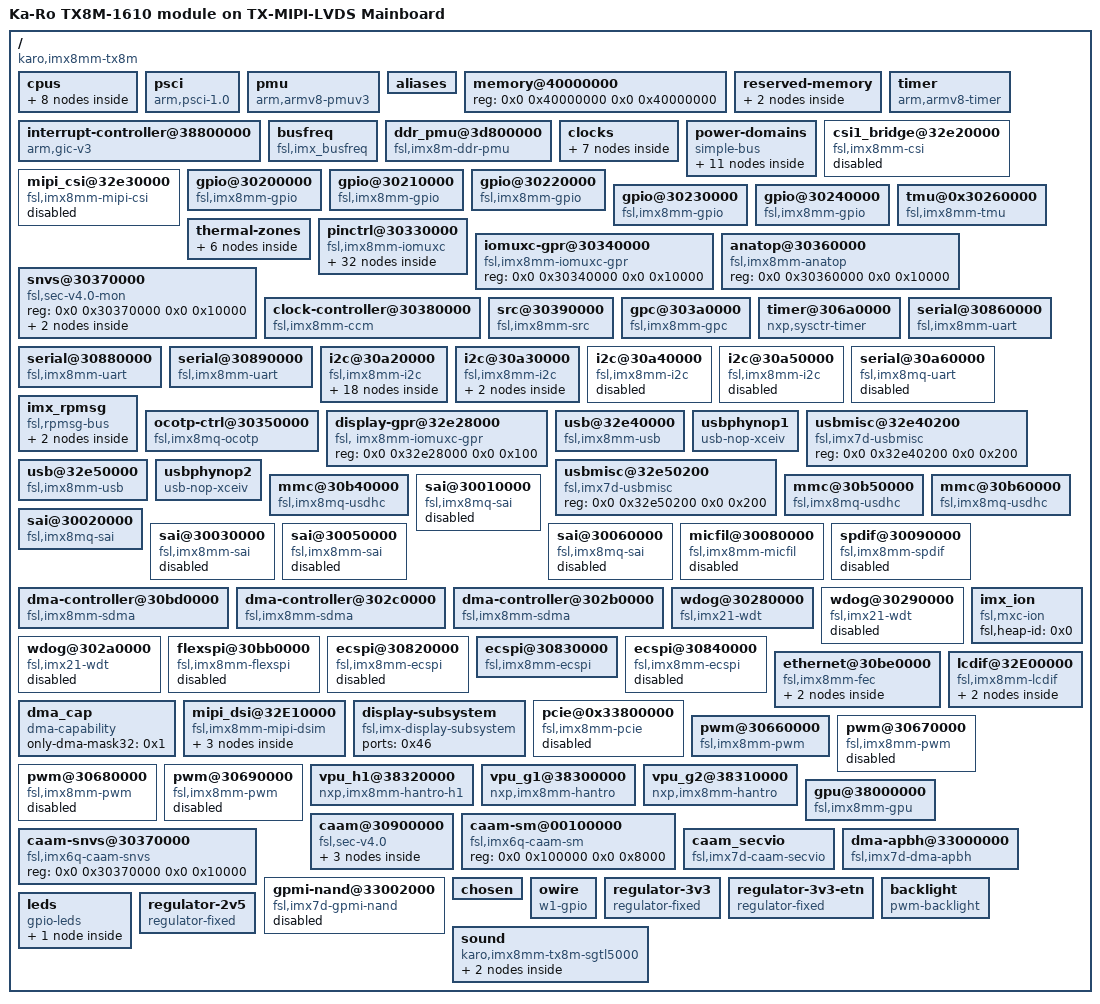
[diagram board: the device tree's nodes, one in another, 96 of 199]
/dts-v1/;

/ {
	compatible = "karo,imx8mm-tx8m", "fsl,imx8mm";
	interrupt-parent = <0x1>;
	#address-cells = <0x2>;
	#size-cells = <0x2>;
	model = "Ka-Ro TX8M-1610 module on TX-MIPI-LVDS Mainboard";

	cpus {
		#address-cells = <0x2>;
		#size-cells = <0x0>;

		idle-states {
			entry-method = "psci";

			cpu-sleep {
				compatible = "arm,idle-state";
				arm,psci-suspend-param = <0x10033>;
				entry-latency-us = <0x61a8>;
				exit-latency-us = <0x2710>;
				min-residency-us = <0x7530>;
				local-timer-stop;
				wakeup-latency-us = <0x3a98>;
			};

			cluster-sleep {
				compatible = "arm,idle-state";
				arm,psci-suspend-param = <0x1000000>;
				entry-latency-us = <0x3e8>;
				exit-latency-us = <0x2bc>;
				min-residency-us = <0xa8c>;
				wakeup-latency-us = <0x5dc>;
			};
		};

		cpu@0 {
			device_type = "cpu";
			compatible = "arm,cortex-a53";
			reg = <0x0 0x0>;
			enable-method = "psci";
			next-level-cache = <0x2>;
			operating-points = <0x1b7740 0xf4240 0x186a00 0xdbba0 0x124f80 0xc3500>;
			clocks = <0x3 0x4c 0x3 0x42 0x3 0x18 0x3 0x2c 0x3 0x38>;
			clock-names = "a53", "arm_a53_src", "arm_pll", "arm_pll_out", "sys1_pll_800m";
			clock-latency = <0xee6c>;
			#cooling-cells = <0x2>;
			arm-supply = <0x4>;
			linux,phandle = <0x5>;
			phandle = <0x5>;
		};

		cpu@1 {
			device_type = "cpu";
			compatible = "arm,cortex-a53";
			reg = <0x0 0x1>;
			enable-method = "psci";
			next-level-cache = <0x2>;
			linux,phandle = <0x6>;
			phandle = <0x6>;
		};

		cpu@2 {
			device_type = "cpu";
			compatible = "arm,cortex-a53";
			reg = <0x0 0x2>;
			enable-method = "psci";
			next-level-cache = <0x2>;
			linux,phandle = <0x7>;
			phandle = <0x7>;
		};

		cpu@3 {
			device_type = "cpu";
			compatible = "arm,cortex-a53";
			reg = <0x0 0x3>;
			enable-method = "psci";
			next-level-cache = <0x2>;
			linux,phandle = <0x8>;
			phandle = <0x8>;
		};

		l2-cache0 {
			compatible = "cache";
			linux,phandle = <0x2>;
			phandle = <0x2>;
		};
	};

	psci {
		compatible = "arm,psci-1.0";
		method = "smc";
		cpu_suspend = <0xc4000001>;
		cpu_off = <0xc4000002>;
		cpu_on = <0xc4000003>;
	};

	pmu {
		compatible = "arm,armv8-pmuv3";
		interrupts = <0x1 0x7 0x3f04>;
		interrupt-affinity = <0x5 0x6 0x7 0x8>;
		interrupt-parent = <0x9>;
	};

	aliases {
		ethernet0 = "/ethernet@30be0000";
		i2c0 = "/i2c@30a20000";
		i2c1 = "/i2c@30a30000";
		i2c2 = "/i2c@30a40000";
		i2c3 = "/i2c@30a50000";
		serial0 = "/serial@30860000";
		serial1 = "/serial@30890000";
		serial2 = "/serial@30880000";
		serial3 = "/serial@30a60000";
		spi0 = "/ecspi@30820000";
		spi1 = "/ecspi@30830000";
		spi2 = "/ecspi@30840000";
		mmc0 = "/mmc@30b40000";
		mmc1 = "/mmc@30b50000";
		mmc2 = "/mmc@30b60000";
		gpio0 = "/gpio@30200000";
		gpio1 = "/gpio@30210000";
		gpio2 = "/gpio@30220000";
		gpio3 = "/gpio@30230000";
		gpio4 = "/gpio@30240000";
		usb-host = "/usb@32e50000";
		usbotg = "/usb@32e40000";
	};

	memory@40000000 {
		device_type = "memory";
		reg = <0x0 0x40000000 0x0 0x40000000>;
	};

	reserved-memory {
		#address-cells = <0x2>;
		#size-cells = <0x2>;
		ranges;

		linux,cma {
			compatible = "shared-dma-pool";
			reusable;
			size = <0x0 0x28000000>;
			alloc-ranges = <0x0 0x40000000 0x0 0x60000000>;
			linux,cma-default;
		};

		rpmsg@0xb8000000 {
			no-map;
			reg = <0x0 0xb8000000 0x0 0x400000>;
			linux,phandle = <0x47>;
			phandle = <0x47>;
		};
	};

	interrupt-controller@38800000 {
		compatible = "arm,gic-v3";
		reg = <0x0 0x38800000 0x0 0x10000 0x0 0x38880000 0x0 0xc0000>;
		#interrupt-cells = <0x3>;
		interrupt-controller;
		interrupts = <0x1 0x9 0x4>;
		interrupt-parent = <0x9>;
		linux,phandle = <0x9>;
		phandle = <0x9>;
	};

	timer {
		compatible = "arm,armv8-timer";
		interrupts = <0x1 0xd 0x3f08 0x1 0xe 0x3f08 0x1 0xb 0x3f08 0x1 0xa 0x3f08>;
		clock-frequency = <0x7a1200>;
		arm,no-tick-in-suspend;
		interrupt-parent = <0x9>;
	};

	busfreq {
		compatible = "fsl,imx_busfreq";
		clocks = <0x3 0x29 0x3 0x90 0x3 0x91 0x3 0x10b 0x3 0x1c5 0x3 0x1c6 0x3 0x30 0x3 0x32 0x3 0x3f 0x3 0x7f 0x3 0x8a 0x3 0x51 0x3 0x2 0x3 0x38>;
		clock-names = "dram_pll", "dram_alt_src", "dram_apb_src", "dram_apb_pre_div", "dram_core", "dram_alt_root", "sys_pll1_40m", "sys_pll1_100m", "sys_pll2_333m", "noc_div", "ahb_div", "main_axi_src", "osc_24m", "sys_pll1_800m";
		interrupts = <0x0 0x4a 0x4 0x0 0x4b 0x4 0x0 0x4c 0x4 0x0 0x4d 0x4>;
		interrupt-name = "irq_busfreq_0", "irq_busfreq_1", "irq_busfreq_2", "irq_busfreq_3";
	};

	ddr_pmu@3d800000 {
		compatible = "fsl,imx8m-ddr-pmu", "fsl,imx8-ddr-pmu";
		reg = <0x0 0x3d800000 0x0 0x400000>;
		interrupts = <0x0 0x62 0x4>;
	};

	clocks {
		#address-cells = <0x1>;
		#size-cells = <0x0>;

		clock@0 {
			compatible = "fixed-clock";
			reg = <0x0>;
			#clock-cells = <0x0>;
			clock-frequency = <0x8000>;
			clock-output-names = "osc_32k";
			linux,phandle = <0x11>;
			phandle = <0x11>;
		};

		clock@1 {
			compatible = "fixed-clock";
			reg = <0x1>;
			#clock-cells = <0x0>;
			clock-frequency = <0x16e3600>;
			clock-output-names = "osc_24m";
			linux,phandle = <0x12>;
			phandle = <0x12>;
		};

		clock@2 {
			compatible = "fixed-clock";
			reg = <0x3>;
			#clock-cells = <0x0>;
			clock-frequency = <0x7ed6b40>;
			clock-output-names = "clk_ext1";
			linux,phandle = <0x13>;
			phandle = <0x13>;
		};

		clock@3 {
			compatible = "fixed-clock";
			reg = <0x4>;
			#clock-cells = <0x0>;
			clock-frequency = <0x7ed6b40>;
			clock-output-names = "clk_ext2";
			linux,phandle = <0x14>;
			phandle = <0x14>;
		};

		clock@4 {
			compatible = "fixed-clock";
			reg = <0x5>;
			#clock-cells = <0x0>;
			clock-frequency = <0x7ed6b40>;
			clock-output-names = "clk_ext3";
			linux,phandle = <0x15>;
			phandle = <0x15>;
		};

		clock@5 {
			compatible = "fixed-clock";
			reg = <0x6>;
			#clock-cells = <0x0>;
			clock-frequency = <0x7ed6b40>;
			clock-output-names = "clk_ext4";
			linux,phandle = <0x16>;
			phandle = <0x16>;
		};

		clock@6 {
			compatible = "fixed-clock";
			reg = <0x6>;
			#clock-cells = <0x0>;
			clock-frequency = <0x18cba80>;
			linux,phandle = <0x25>;
			phandle = <0x25>;
		};
	};

	power-domains {
		compatible = "simple-bus";
		#address-cells = <0x1>;
		#size-cells = <0x0>;

		power-domain@0 {
			compatible = "fsl,imx8mm-pm-domain";
			#address-cells = <0x1>;
			#size-cells = <0x0>;
			domain-id = <0x0>;
			#power-domain-cells = <0x0>;
			domain-name = "HSIO_PD";
			clocks = <0x3 0x1a5>;

			power-domain@1 {
				domain-id = <0x1>;
				#power-domain-cells = <0x0>;
				domain-name = "PCIE0_PD";
				clocks = <0x3 0x18e>;
				linux,phandle = <0x48>;
				phandle = <0x48>;
			};

			power-domain@2 {
				domain-id = <0x2>;
				#power-domain-cells = <0x0>;
				domain-name = "USB_OTG1_PD";
				linux,phandle = <0x29>;
				phandle = <0x29>;
			};

			power-domain@3 {
				domain-id = <0x3>;
				#power-domain-cells = <0x0>;
				domain-name = "USB_OTG2_PD";
				linux,phandle = <0x2c>;
				phandle = <0x2c>;
			};
		};

		power-domain@4 {
			compatible = "fsl,imx8mm-pm-domain";
			domain-id = <0x4>;
			#power-domain-cells = <0x0>;
			domain-name = "GPUMIX_PD";
			clocks = <0x3 0x1ad 0x3 0x1be 0x3 0x1a6 0x3 0x7e>;
			linux,phandle = <0x4d>;
			phandle = <0x4d>;
		};

		power-domain@5 {
			compatible = "fsl,imx8mm-pm-domain";
			#address-cells = <0x1>;
			#size-cells = <0x0>;
			domain-id = <0x5>;
			#power-domain-cells = <0x0>;
			domain-name = "VPUMIX_PD";
			clocks = <0x3 0x1b7>;

			power-domain@6 {
				domain-id = <0x6>;
				#power-domain-cells = <0x0>;
				domain-name = "VPU_G1_PD";
				clocks = <0x3 0x1ac>;
				linux,phandle = <0x4b>;
				phandle = <0x4b>;
			};

			power-domain@7 {
				domain-id = <0x7>;
				#power-domain-cells = <0x0>;
				domain-name = "VPU_G2_PD";
				clocks = <0x3 0x1af>;
				linux,phandle = <0x4c>;
				phandle = <0x4c>;
			};

			power-domain@8 {
				domain-id = <0x8>;
				#power-domain-cells = <0x0>;
				domain-name = "VPU_H1_PD";
				clocks = <0x3 0x1ae>;
				linux,phandle = <0x4a>;
				phandle = <0x4a>;
			};
		};

		power-domain@9 {
			compatible = "fsl,imx8mm-pm-domain";
			#address-cells = <0x1>;
			#size-cells = <0x0>;
			domain-id = <0x9>;
			#power-domain-cells = <0x0>;
			domain-name = "DISPMIX_PD";
			clocks = <0x3 0x1b1>;
			linux,phandle = <0xa>;
			phandle = <0xa>;

			power-domain@10 {
				domain-id = <0xa>;
				#power-domain-cells = <0x0>;
				domain-name = "MIPI_PD";
				linux,phandle = <0xc>;
				phandle = <0xc>;
			};
		};
	};

	csi1_bridge@32e20000 {
		compatible = "fsl,imx8mm-csi", "fsl,imx8mq-csi", "fsl,imx6s-csi";
		reg = <0x0 0x32e20000 0x0 0x10000>;
		interrupts = <0x0 0x10 0x4>;
		clocks = <0x3 0x1b2 0x3 0x1c0 0x3 0x1b3>;
		clock-names = "disp-axi", "csi_mclk", "disp_dcic";
		power-domains = <0xa>;
		status = "disabled";
	};

	mipi_csi@32e30000 {
		compatible = "fsl,imx8mm-mipi-csi";
		reg = <0x0 0x32e30000 0x0 0x1000>;
		interrupts = <0x0 0x11 0x4>;
		clock-frequency = <0x13d92d40>;
		clocks = <0x3 0x178 0x3 0x179 0x3 0x1b2 0x3 0x1b3>;
		clock-names = "mipi_clk", "phy_clk", "disp_axi", "disp_apb";
		bus-width = <0x4>;
		csi-gpr = <0xb>;
		power-domains = <0xc>;
		status = "disabled";
	};

	gpio@30200000 {
		compatible = "fsl,imx8mm-gpio", "fsl,imx35-gpio";
		reg = <0x0 0x30200000 0x0 0x10000>;
		interrupts = <0x0 0x40 0x4 0x0 0x41 0x4>;
		gpio-controller;
		#gpio-cells = <0x2>;
		interrupt-controller;
		#interrupt-cells = <0x2>;
		linux,phandle = <0x21>;
		phandle = <0x21>;
	};

	gpio@30210000 {
		compatible = "fsl,imx8mm-gpio", "fsl,imx35-gpio";
		reg = <0x0 0x30210000 0x0 0x10000>;
		interrupts = <0x0 0x42 0x4 0x0 0x43 0x4>;
		gpio-controller;
		#gpio-cells = <0x2>;
		interrupt-controller;
		#interrupt-cells = <0x2>;
		linux,phandle = <0x32>;
		phandle = <0x32>;
	};

	gpio@30220000 {
		compatible = "fsl,imx8mm-gpio", "fsl,imx35-gpio";
		reg = <0x0 0x30220000 0x0 0x10000>;
		interrupts = <0x0 0x44 0x4 0x0 0x45 0x4>;
		gpio-controller;
		#gpio-cells = <0x2>;
		interrupt-controller;
		#interrupt-cells = <0x2>;
		linux,phandle = <0x37>;
		phandle = <0x37>;
	};

	gpio@30230000 {
		compatible = "fsl,imx8mm-gpio", "fsl,imx35-gpio";
		reg = <0x0 0x30230000 0x0 0x10000>;
		interrupts = <0x0 0x46 0x4 0x0 0x47 0x4>;
		gpio-controller;
		#gpio-cells = <0x2>;
		interrupt-controller;
		#interrupt-cells = <0x2>;
	};

	gpio@30240000 {
		compatible = "fsl,imx8mm-gpio", "fsl,imx35-gpio";
		reg = <0x0 0x30240000 0x0 0x10000>;
		interrupts = <0x0 0x48 0x4 0x0 0x49 0x4>;
		gpio-controller;
		#gpio-cells = <0x2>;
		interrupt-controller;
		#interrupt-cells = <0x2>;
		linux,phandle = <0x44>;
		phandle = <0x44>;
	};

	tmu@0x30260000 {
		compatible = "fsl,imx8mm-tmu";
		reg = <0x0 0x30260000 0x0 0x10000>;
		clocks = <0x3 0x1b6>;
		interrupt = <0x0 0x31 0x4>;
		#thermal-sensor-cells = <0x0>;
		linux,phandle = <0xd>;
		phandle = <0xd>;
	};

	thermal-zones {

		cpu-thermal {
			polling-delay-passive = <0xfa>;
			polling-delay = <0x7d0>;
			thermal-sensors = <0xd>;

			trips {

				trip0 {
					temperature = <0x14c08>;
					hysteresis = <0x7d0>;
					type = "passive";
					linux,phandle = <0xe>;
					phandle = <0xe>;
				};

				trip1 {
					temperature = <0x17318>;
					hysteresis = <0x7d0>;
					type = "critical";
				};
			};

			cooling-maps {

				map0 {
					trip = <0xe>;
					cooling-device = <0x5 0xffffffff 0xffffffff>;
				};
			};
		};
	};

	pinctrl@30330000 {
		compatible = "fsl,imx8mm-iomuxc";
		reg = <0x0 0x30330000 0x0 0x10000>;
		pinctrl-names = "default";
		pinctrl-0 = <0xf>;

		hoggrp {
			fsl,pins;
			linux,phandle = <0xf>;
			phandle = <0xf>;
		};

		etnphy-intgrp {
			fsl,pins = <0x98 0x300 0x0 0x5 0x0 0x90>;
			linux,phandle = <0x40>;
			phandle = <0x40>;
		};

		etnphy-powergrp {
			fsl,pins = <0x84 0x2ec 0x0 0x5 0x0 0x142>;
			linux,phandle = <0x51>;
			phandle = <0x51>;
		};

		etnphy-rstgrp {
			fsl,pins = <0x9c 0x304 0x0 0x5 0x0 0x140>;
			linux,phandle = <0x3c>;
			phandle = <0x3c>;
		};

		fec1grp {
			fsl,pins = <0x68 0x2d0 0x0 0x0 0x0 0x142 0x6c 0x2d4 0x4c0 0x0 0x1 0x142 0x74 0x2dc 0x0 0x1 0x0 0x40000016 0x7c 0x2e4 0x0 0x0 0x0 0x16 0x78 0x2e0 0x0 0x0 0x0 0x16 0x90 0x2f8 0x0 0x0 0x0 0x90 0x94 0x2fc 0x0 0x0 0x0 0x90 0x8c 0x2f4 0x0 0x1 0x0 0x16 0x88 0x2f0 0x0 0x0 0x0 0x16 0x80 0x2e8 0x0 0x0 0x0 0x16>;
			linux,phandle = <0x3b>;
			phandle = <0x3b>;
		};

		fec1-sleepgrp {
			fsl,pins = <0x68 0x2d0 0x0 0x0 0x0 0x120 0x6c 0x2d4 0x4c0 0x0 0x1 0x120 0x74 0x2dc 0x0 0x1 0x0 0x40000120 0x7c 0x2e4 0x0 0x0 0x0 0x120 0x78 0x2e0 0x0 0x0 0x0 0x120 0x90 0x2f8 0x0 0x0 0x0 0x120 0x94 0x2fc 0x0 0x0 0x0 0x120 0x8c 0x2f4 0x0 0x1 0x0 0x120 0x88 0x2f0 0x0 0x0 0x0 0x120 0x80 0x2e8 0x0 0x0 0x0 0x120>;
			linux,phandle = <0x3d>;
			phandle = <0x3d>;
		};

		i2c1grp {
			fsl,pins = <0x214 0x47c 0x0 0x0 0x0 0x400001d6 0x218 0x480 0x0 0x0 0x0 0x400001d6>;
			linux,phandle = <0x1e>;
			phandle = <0x1e>;
		};

		i2c1-gpiogrp {
			fsl,pins = <0x214 0x47c 0x0 0x5 0x0 0x400001d6 0x218 0x480 0x0 0x5 0x0 0x400001d6>;
			linux,phandle = <0x1f>;
			phandle = <0x1f>;
		};

		i2c2grp {
			fsl,pins = <0x21c 0x484 0x0 0x0 0x0 0x400001d6 0x220 0x488 0x0 0x0 0x0 0x400001d6>;
			linux,phandle = <0x22>;
			phandle = <0x22>;
		};

		i2c3grp {
			fsl,pins = <0x224 0x48c 0x0 0x0 0x0 0x400001d6 0x228 0x490 0x0 0x0 0x0 0x400001d6>;
			linux,phandle = <0x26>;
			phandle = <0x26>;
		};

		i2c4grp {
			fsl,pins = <0x22c 0x494 0x0 0x0 0x0 0x400001d6 0x230 0x498 0x0 0x0 0x0 0x400001d6>;
		};

		owiregrp {
			fsl,pins = <0x158 0x3c0 0x0 0x5 0x0 0x400001c0>;
			linux,phandle = <0x4f>;
			phandle = <0x4f>;
		};

		pmicgrp {
			fsl,pins = <0x34 0x29c 0x0 0x0 0x0 0x1c0>;
			linux,phandle = <0x20>;
			phandle = <0x20>;
		};

		uart1grp {
			fsl,pins = <0x234 0x49c 0x4f4 0x0 0x0 0x140 0x238 0x4a0 0x0 0x0 0x0 0x140>;
			linux,phandle = <0x18>;
			phandle = <0x18>;
		};

		uart1-rtsctsgrp {
			fsl,pins = <0x248 0x4b0 0x4f0 0x1 0x1 0x140 0x244 0x4ac 0x0 0x1 0x0 0x140>;
			linux,phandle = <0x19>;
			phandle = <0x19>;
		};

		uart2grp {
			fsl,pins = <0x23c 0x4a4 0x4fc 0x0 0x0 0x140 0x240 0x4a8 0x0 0x0 0x0 0x140>;
			linux,phandle = <0x1c>;
			phandle = <0x1c>;
		};

		uart2-rtsctsgrp {
			fsl,pins = <0x250 0x4b8 0x4f8 0x1 0x1 0x140 0x24c 0x4b4 0x0 0x1 0x0 0x140>;
			linux,phandle = <0x1d>;
			phandle = <0x1d>;
		};

		uart3grp {
			fsl,pins = <0x1f4 0x45c 0x504 0x1 0x0 0x140 0x1f8 0x460 0x0 0x1 0x0 0x140>;
			linux,phandle = <0x1a>;
			phandle = <0x1a>;
		};

		uart3-rtsctsgrp {
			fsl,pins = <0x200 0x468 0x500 0x1 0x1 0x140 0x1fc 0x464 0x0 0x1 0x0 0x140>;
			linux,phandle = <0x1b>;
			phandle = <0x1b>;
		};

		usdhc1grp {
			fsl,pins = <0xa0 0x308 0x0 0x0 0x0 0x190 0xa4 0x30c 0x0 0x0 0x0 0x1d0 0xa8 0x310 0x0 0x0 0x0 0x1d0 0xac 0x314 0x0 0x0 0x0 0x1d0 0xb0 0x318 0x0 0x0 0x0 0x1d0 0xb4 0x31c 0x0 0x0 0x0 0x1d0 0xb8 0x320 0x0 0x0 0x0 0x1d0 0xbc 0x324 0x0 0x0 0x0 0x1d0 0xc0 0x328 0x0 0x0 0x0 0x1d0 0xc4 0x32c 0x0 0x0 0x0 0x1d0 0xcc 0x334 0x0 0x0 0x0 0x156 0xc8 0x330 0x0 0x0 0x0 0x156>;
			linux,phandle = <0x2d>;
			phandle = <0x2d>;
		};

		usdhc2grp {
			fsl,pins = <0xd4 0x33c 0x0 0x0 0x0 0x190 0xd8 0x340 0x0 0x0 0x0 0x1d0 0xdc 0x344 0x0 0x0 0x0 0x1d0 0xe0 0x348 0x0 0x0 0x0 0x1d0 0xe4 0x34c 0x0 0x0 0x0 0x1d0 0xe8 0x350 0x0 0x0 0x0 0x1d0>;
			linux,phandle = <0x2e>;
			phandle = <0x2e>;
		};

		usdhc2grp100mhz {
			fsl,pins = <0xd4 0x33c 0x0 0x0 0x0 0x194 0xd8 0x340 0x0 0x0 0x0 0x1d4 0xdc 0x344 0x0 0x0 0x0 0x1d4 0xe0 0x348 0x0 0x0 0x0 0x1d4 0xe4 0x34c 0x0 0x0 0x0 0x1d4 0xe8 0x350 0x0 0x0 0x0 0x1d4>;
			linux,phandle = <0x30>;
			phandle = <0x30>;
		};

		usdhc2grp200mhz {
			fsl,pins = <0xd4 0x33c 0x0 0x0 0x0 0x196 0xd8 0x340 0x0 0x0 0x0 0x1d6 0xdc 0x344 0x0 0x0 0x0 0x1d6 0xe0 0x348 0x0 0x0 0x0 0x1d6 0xe4 0x34c 0x0 0x0 0x0 0x1d6 0xe8 0x350 0x0 0x0 0x0 0x1d6>;
			linux,phandle = <0x31>;
			phandle = <0x31>;
		};

		usdhc2-cdgrp {
			fsl,pins = <0xd0 0x338 0x0 0x5 0x0 0x1c0>;
			linux,phandle = <0x2f>;
			phandle = <0x2f>;
		};

		usdhc3grp {
			fsl,pins = <0x138 0x3a0 0x0 0x12 0x0 0x40000190 0x13c 0x3a4 0x0 0x2 0x0 0x1d0 0x11c 0x384 0x0 0x2 0x0 0x1d0 0x120 0x388 0x0 0x2 0x0 0x1d0 0x124 0x38c 0x0 0x2 0x0 0x1d0 0x128 0x390 0x0 0x2 0x0 0x1d0>;
			linux,phandle = <0x33>;
			phandle = <0x33>;
		};

		usdhc3grp100mhz {
			fsl,pins = <0x138 0x3a0 0x0 0x12 0x0 0x40000194 0x13c 0x3a4 0x0 0x2 0x0 0x1d4 0x11c 0x384 0x0 0x2 0x0 0x1d4 0x120 0x388 0x0 0x2 0x0 0x1d4 0x124 0x38c 0x0 0x2 0x0 0x1d4 0x128 0x390 0x0 0x2 0x0 0x1d4>;
			linux,phandle = <0x35>;
			phandle = <0x35>;
		};

		usdhc3grp200mhz {
			fsl,pins = <0x138 0x3a0 0x0 0x12 0x0 0x40000196 0x13c 0x3a4 0x0 0x2 0x0 0x1d6 0x11c 0x384 0x0 0x2 0x0 0x1d6 0x120 0x388 0x0 0x2 0x0 0x1d6 0x124 0x38c 0x0 0x2 0x0 0x1d6 0x128 0x390 0x0 0x2 0x0 0x1d6>;
			linux,phandle = <0x36>;
			phandle = <0x36>;
		};

		usdhc3-cdgrp {
			fsl,pins = <0x114 0x37c 0x0 0x5 0x0 0x1c0>;
			linux,phandle = <0x34>;
			phandle = <0x34>;
		};

		pwm1grp {
			fsl,pins = <0x2c 0x294 0x0 0x1 0x0 0x6>;
			linux,phandle = <0x49>;
			phandle = <0x49>;
		};

		sai2grp {
			fsl,pins = <0x1b8 0x420 0x0 0x0 0x0 0xd6 0x1c4 0x42c 0x0 0x0 0x0 0xd6 0x1c0 0x428 0x0 0x0 0x0 0xd6 0x1bc 0x424 0x0 0x0 0x0 0xd6>;
			linux,phandle = <0x39>;
			phandle = <0x39>;
		};

		stk5ledgrp {
			fsl,pins = <0x30 0x298 0x0 0x0 0x0 0x6>;
			linux,phandle = <0x53>;
			phandle = <0x53>;
		};

		tm101grp {
			fsl,pins = <0x22c 0x494 0x0 0x5 0x0 0x146>;
			linux,phandle = <0x43>;
			phandle = <0x43>;
		};
	};

	iomuxc-gpr@30340000 {
		compatible = "fsl,imx8mm-iomuxc-gpr", "fsl,imx7d-iomuxc-gpr", "syscon";
		reg = <0x0 0x30340000 0x0 0x10000>;
		linux,phandle = <0x3a>;
		phandle = <0x3a>;
	};

	anatop@30360000 {
		compatible = "fsl,imx8mm-anatop", "syscon", "simple-bus";
		reg = <0x0 0x30360000 0x0 0x10000>;
	};

	snvs@30370000 {
		compatible = "fsl,sec-v4.0-mon", "syscon", "simple-mfd";
		reg = <0x0 0x30370000 0x0 0x10000>;
		linux,phandle = <0x10>;
		phandle = <0x10>;

		snvs-rtc-lp {
			compatible = "fsl,sec-v4.0-mon-rtc-lp";
			regmap = <0x10>;
			offset = <0x34>;
			interrupts = <0x0 0x13 0x4 0x0 0x14 0x4>;
		};

		snvs-powerkey {
			compatible = "fsl,sec-v4.0-pwrkey";
			regmap = <0x10>;
			interrupts = <0x0 0x4 0x4>;
			linux,keycode = <0x74>;
			wakeup-source;
		};
	};

	clock-controller@30380000 {
		compatible = "fsl,imx8mm-ccm";
		reg = <0x0 0x30380000 0x0 0x10000>;
		#clock-cells = <0x1>;
		clocks = <0x11 0x12 0x13 0x14 0x15 0x16>;
		clock-names = "osc_32k", "osc_24m", "clk_ext1", "clk_ext2", "clk_ext3", "clk_ext4";
		linux,phandle = <0x3>;
		phandle = <0x3>;
	};

	src@30390000 {
		compatible = "fsl,imx8mm-src", "fsl,imx8mq-src", "syscon";
		reg = <0x0 0x30390000 0x0 0x10000>;
		interrupts = <0x0 0x59 0x4>;
		#reset-cells = <0x1>;
	};

	gpc@303a0000 {
		compatible = "fsl,imx8mm-gpc", "fsl,imx8mq-gpc", "syscon";
		reg = <0x0 0x303a0000 0x0 0x10000>;
		interrupt-controller;
		interrupts = <0x0 0x57 0x4>;
		#interrupt-cells = <0x3>;
		interrupt-parent = <0x9>;
		linux,phandle = <0x1>;
		phandle = <0x1>;
	};

	timer@306a0000 {
		compatible = "nxp,sysctr-timer";
		reg = <0x0 0x306a0000 0x0 0x10000 0x0 0x306b0000 0x0 0x10000 0x0 0x306c0000 0x0 0x10000>;
		clock-frequency = <0x7a1200>;
		interrupts = <0x0 0x2f 0x4 0x0 0x30 0x4>;
	};

	serial@30860000 {
		compatible = "fsl,imx8mm-uart", "fsl,imx6q-uart", "fsl,imx21-uart";
		reg = <0x0 0x30860000 0x0 0x10000>;
		interrupts = <0x0 0x1a 0x4>;
		clocks = <0x3 0x1a1 0x3 0x1a1>;
		clock-names = "ipg", "per";
		dmas = <0x17 0x16 0x4 0x0 0x17 0x17 0x4 0x0>;
		dma-names = "rx", "tx";
		status = "okay";
		pinctrl-names = "default";
		pinctrl-0 = <0x18 0x19>;
		uart-has-rtscts;
	};

	serial@30880000 {
		compatible = "fsl,imx8mm-uart", "fsl,imx6q-uart", "fsl,imx21-uart";
		reg = <0x0 0x30880000 0x0 0x10000>;
		interrupts = <0x0 0x1c 0x4>;
		clocks = <0x3 0x1a3 0x3 0x1a3>;
		clock-names = "ipg", "per";
		dmas = <0x17 0x1a 0x4 0x0 0x17 0x1b 0x4 0x0>;
		dma-names = "rx", "tx";
		status = "okay";
		pinctrl-names = "default";
		pinctrl-0 = <0x1a 0x1b>;
		uart-has-rtscts;
	};

	serial@30890000 {
		compatible = "fsl,imx8mm-uart", "fsl,imx6q-uart", "fsl,imx21-uart";
		reg = <0x0 0x30890000 0x0 0x10000>;
		interrupts = <0x0 0x1b 0x4>;
		clocks = <0x3 0x1a2 0x3 0x1a2>;
		clock-names = "ipg", "per";
		status = "okay";
		pinctrl-names = "default";
		pinctrl-0 = <0x1c 0x1d>;
		uart-has-rtscts;
	};

	i2c@30a20000 {
		#address-cells = <0x1>;
		#size-cells = <0x0>;
		compatible = "fsl,imx8mm-i2c", "fsl,imx21-i2c";
		reg = <0x0 0x30a20000 0x0 0x10000>;
		interrupts = <0x0 0x23 0x4>;
		clocks = <0x3 0x189>;
		status = "okay";
		pinctrl-names = "default", "gpio";
		pinctrl-0 = <0x1e>;
		pinctrl-1 = <0x1f>;
		clock-frequency = <0x61a80>;

		bd71837@4b {
			reg = <0x4b>;
			compatible = "rohm,bd71837";
			pinctrl-0 = <0x20>;
			gpio_intr = <0x21 0x3 0x1>;

			gpo {
				rohm,drv = <0xc>;
			};

			regulators {
				#address-cells = <0x1>;
				#size-cells = <0x0>;
				bd71837,pmic-buck2-uses-i2c-dvs;
				bd71837,pmic-buck2-dvs-voltage = <0xf4240 0xdbba0 0x0>;

				regulator@0 {
					reg = <0x0>;
					regulator-compatible = "buck1";
					regulator-min-microvolt = <0xaae60>;
					regulator-max-microvolt = <0x13d620>;
					regulator-boot-on;
					regulator-always-on;
					regulator-ramp-delay = <0x4e2>;
				};

				regulator@1 {
					reg = <0x1>;
					regulator-compatible = "buck2";
					regulator-min-microvolt = <0xaae60>;
					regulator-max-microvolt = <0x13d620>;
					regulator-boot-on;
					regulator-always-on;
					regulator-ramp-delay = <0x4e2>;
					linux,phandle = <0x4>;
					phandle = <0x4>;
				};

				regulator@2 {
					reg = <0x2>;
					regulator-compatible = "buck3";
					regulator-min-microvolt = <0xaae60>;
					regulator-max-microvolt = <0x13d620>;
				};

				regulator@3 {
					reg = <0x3>;
					regulator-compatible = "buck4";
					regulator-min-microvolt = <0xaae60>;
					regulator-max-microvolt = <0x13d620>;
				};

				regulator@4 {
					reg = <0x4>;
					regulator-compatible = "buck5";
					regulator-min-microvolt = <0xaae60>;
					regulator-max-microvolt = <0x149970>;
					regulator-boot-on;
					regulator-always-on;
				};

				regulator@5 {
					reg = <0x5>;
					regulator-compatible = "buck6";
					regulator-min-microvolt = <0x2dc6c0>;
					regulator-max-microvolt = <0x325aa0>;
					regulator-boot-on;
					regulator-always-on;
					linux,phandle = <0x50>;
					phandle = <0x50>;
				};

				regulator@6 {
					reg = <0x6>;
					regulator-compatible = "buck7";
					regulator-min-microvolt = <0x187d88>;
					regulator-max-microvolt = <0x1e70f8>;
					regulator-boot-on;
					regulator-always-on;
				};

				regulator@7 {
					reg = <0x7>;
					regulator-compatible = "buck8";
					regulator-min-microvolt = <0xc3500>;
					regulator-max-microvolt = <0x155cc0>;
					regulator-boot-on;
					regulator-always-on;
				};

				regulator@8 {
					reg = <0x8>;
					regulator-compatible = "ldo1";
					regulator-min-microvolt = <0x2dc6c0>;
					regulator-max-microvolt = <0x325aa0>;
					regulator-boot-on;
					regulator-always-on;
				};

				regulator@9 {
					reg = <0x9>;
					regulator-compatible = "ldo2";
					regulator-min-microvolt = <0xdbba0>;
					regulator-max-microvolt = <0xdbba0>;
					regulator-boot-on;
					regulator-always-on;
				};

				regulator@10 {
					reg = <0xa>;
					regulator-compatible = "ldo3";
					regulator-min-microvolt = <0x1b7740>;
					regulator-max-microvolt = <0x325aa0>;
					regulator-boot-on;
					regulator-always-on;
				};

				regulator@11 {
					reg = <0xb>;
					regulator-compatible = "ldo4";
					regulator-min-microvolt = <0xdbba0>;
					regulator-max-microvolt = <0x1b7740>;
					regulator-boot-on;
					regulator-always-on;
				};

				regulator@12 {
					reg = <0xc>;
					regulator-compatible = "ldo5";
					regulator-min-microvolt = <0x1b7740>;
					regulator-max-microvolt = <0x325aa0>;
				};

				regulator@13 {
					reg = <0xd>;
					regulator-compatible = "ldo6";
					regulator-min-microvolt = <0xdbba0>;
					regulator-max-microvolt = <0x1b7740>;
					regulator-boot-on;
					regulator-always-on;
				};

				regulator@14 {
					reg = <0xe>;
					regulator-compatible = "ldo7";
					regulator-min-microvolt = <0x1b7740>;
					regulator-max-microvolt = <0x325aa0>;
				};
			};
		};
	};

	i2c@30a30000 {
		#address-cells = <0x1>;
		#size-cells = <0x0>;
		compatible = "fsl,imx8mm-i2c", "fsl,imx21-i2c";
		reg = <0x0 0x30a30000 0x0 0x10000>;
		interrupts = <0x0 0x24 0x4>;
		clocks = <0x3 0x18a>;
		status = "okay";
		clock-frequency = <0x61a80>;
		pinctrl-names = "default";
		pinctrl-0 = <0x22>;

		sgtl5000@a {
			compatible = "fsl,sgtl5000";
			reg = <0xa>;
			VDDA-supply = <0x23>;
			VDDIO-supply = <0x24>;
			#sound-dai-cells = <0x0>;
			clocks = <0x25>;
			linux,phandle = <0x56>;
			phandle = <0x56>;
		};

		mcp7940x@6f {
			compatible = "microchip,mcp7940x";
			reg = <0x6f>;
		};
	};

	i2c@30a40000 {
		#address-cells = <0x1>;
		#size-cells = <0x0>;
		compatible = "fsl,imx8mm-i2c", "fsl,imx21-i2c";
		reg = <0x0 0x30a40000 0x0 0x10000>;
		interrupts = <0x0 0x25 0x4>;
		clocks = <0x3 0x18b>;
		status = "disabled";
		clock-frequency = <0x61a80>;
		pinctrl-names = "default";
		pinctrl-0 = <0x26>;
	};

	i2c@30a50000 {
		#address-cells = <0x1>;
		#size-cells = <0x0>;
		compatible = "fsl,imx8mm-i2c", "fsl,imx21-i2c";
		reg = <0x0 0x30a50000 0x0 0x10000>;
		interrupts = <0x0 0x26 0x4>;
		clocks = <0x3 0x18c>;
		status = "disabled";
	};

	serial@30a60000 {
		compatible = "fsl,imx8mq-uart", "fsl,imx6q-uart", "fsl,imx21-uart";
		reg = <0x0 0x30a60000 0x0 0x10000>;
		interrupts = <0x0 0x1d 0x4>;
		clocks = <0x3 0x1a4 0x3 0x1a4>;
		clock-names = "ipg", "per";
		dmas = <0x17 0x1c 0x4 0x0 0x17 0x1d 0x4 0x0>;
		dma-names = "rx", "tx";
		status = "disabled";
	};

	imx_rpmsg {
		compatible = "fsl,rpmsg-bus", "simple-bus";
		#address-cells = <0x2>;
		#size-cells = <0x2>;
		ranges;

		mu@30aa0000 {
			compatible = "fsl,imx8mq-mu", "fsl,imx6sx-mu";
			reg = <0x0 0x30aa0000 0x0 0x10000>;
			interrupts = <0x0 0x58 0x4>;
			clocks = <0x3 0x1bf>;
			clock-names = "mu";
			status = "okay";
		};

		rpmsg {
			compatible = "fsl,imx8qm-rpmsg";
			status = "okay";
			vdev-nums = <0x1>;
			reg = <0x0 0xb8000000 0x0 0x10000>;
		};
	};

	ocotp-ctrl@30350000 {
		compatible = "fsl,imx8mq-ocotp", "fsl,imx7d-ocotp", "syscon";
		reg = <0x0 0x30350000 0x0 0x10000>;
		clocks = <0x3 0x18d>;
		#address-cells = <0x1>;
		#size-cells = <0x1>;
	};

	display-gpr@32e28000 {
		compatible = "fsl, imx8mm-iomuxc-gpr", "syscon";
		reg = <0x0 0x32e28000 0x0 0x100>;
		linux,phandle = <0xb>;
		phandle = <0xb>;
	};

	usb@32e40000 {
		compatible = "fsl,imx8mm-usb", "fsl,imx7d-usb", "fsl,imx27-usb";
		reg = <0x0 0x32e40000 0x0 0x200>;
		interrupts = <0x0 0x28 0x4>;
		clocks = <0x3 0x1a5>;
		clock-names = "usb1_ctrl_root_clk";
		assigned-clocks = <0x3 0x58 0x3 0xb2>;
		assigned-clock-parents = <0x3 0x40 0x3 0x32>;
		fsl,usbphy = <0x27>;
		fsl,usbmisc = <0x28 0x0>;
		power-domains = <0x29>;
		status = "okay";
		dr_mode = "host";
	};

	usbphynop1 {
		compatible = "usb-nop-xceiv";
		clocks = <0x3 0xb3>;
		assigned-clocks = <0x3 0xb3>;
		assigned-clock-parents = <0x3 0x32>;
		clock-names = "main_clk";
		linux,phandle = <0x27>;
		phandle = <0x27>;
	};

	usbmisc@32e40200 {
		#index-cells = <0x1>;
		compatible = "fsl,imx7d-usbmisc", "fsl,imx6q-usbmisc";
		reg = <0x0 0x32e40200 0x0 0x200>;
		linux,phandle = <0x28>;
		phandle = <0x28>;
	};

	usb@32e50000 {
		compatible = "fsl,imx8mm-usb", "fsl,imx7d-usb", "fsl,imx27-usb";
		reg = <0x0 0x32e50000 0x0 0x200>;
		interrupts = <0x0 0x29 0x4>;
		clocks = <0x3 0x1a5>;
		clock-names = "usb1_ctrl_root_clk";
		assigned-clocks = <0x3 0x58 0x3 0xb2>;
		assigned-clock-parents = <0x3 0x40 0x3 0x32>;
		fsl,usbphy = <0x2a>;
		fsl,usbmisc = <0x2b 0x0>;
		power-domains = <0x2c>;
		status = "okay";
		dr_mode = "host";
	};

	usbphynop2 {
		compatible = "usb-nop-xceiv";
		clocks = <0x3 0xb3>;
		assigned-clocks = <0x3 0xb3>;
		assigned-clock-parents = <0x3 0x32>;
		clock-names = "main_clk";
		linux,phandle = <0x2a>;
		phandle = <0x2a>;
	};

	usbmisc@32e50200 {
		#index-cells = <0x1>;
		compatible = "fsl,imx7d-usbmisc", "fsl,imx6q-usbmisc";
		reg = <0x0 0x32e50200 0x0 0x200>;
		linux,phandle = <0x2b>;
		phandle = <0x2b>;
	};

	mmc@30b40000 {
		compatible = "fsl,imx8mq-usdhc", "fsl,imx7d-usdhc";
		reg = <0x0 0x30b40000 0x0 0x10000>;
		interrupts = <0x0 0x16 0x4>;
		clocks = <0x3 0x0 0x3 0x77 0x3 0x1a7>;
		clock-names = "ipg", "ahb", "per";
		assigned-clocks = <0x3 0x15f>;
		assigned-clock-rates = <0x17d78400>;
		fsl,tuning-start-tap = <0x14>;
		fsl,tuning-step = <0x2>;
		bus-width = <0x8>;
		status = "okay";
		pinctrl-names = "default";
		pinctrl-0 = <0x2d>;
		no-1-8-v;
		non-removable;
	};

	mmc@30b50000 {
		compatible = "fsl,imx8mq-usdhc", "fsl,imx7d-usdhc";
		reg = <0x0 0x30b50000 0x0 0x10000>;
		interrupts = <0x0 0x17 0x4>;
		clocks = <0x3 0x0 0x3 0x77 0x3 0x1a8>;
		clock-names = "ipg", "ahb", "per";
		fsl,tuning-start-tap = <0x14>;
		fsl,tuning-step = <0x2>;
		bus-width = <0x4>;
		status = "okay";
		pinctrl-names = "default", "state_100mhz", "state_200mhz";
		pinctrl-0 = <0x2e 0x2f>;
		pinctrl-1 = <0x30 0x2f>;
		pinctrl-2 = <0x31 0x2f>;
		cd-gpios = <0x32 0xc 0x1>;
		no-1-8-v;
		fsl,wp-controller;
	};

	mmc@30b60000 {
		compatible = "fsl,imx8mq-usdhc", "fsl,imx7d-usdhc";
		reg = <0x0 0x30b60000 0x0 0x10000>;
		interrupts = <0x0 0x18 0x4>;
		clocks = <0x3 0x0 0x3 0x77 0x3 0x1b5>;
		clock-names = "ipg", "ahb", "per";
		assigned-clocks = <0x3 0x1b5>;
		assigned-clock-rates = <0x17d78400>;
		fsl,tuning-start-tap = <0x14>;
		fsl,tuning-step = <0x2>;
		bus-width = <0x4>;
		status = "okay";
		pinctrl-names = "default", "state_100mhz", "state_200mhz";
		pinctrl-0 = <0x33 0x34>;
		pinctrl-1 = <0x35 0x34>;
		pinctrl-2 = <0x36 0x34>;
		cd-gpios = <0x37 0x8 0x1>;
		no-1-8-v;
		fsl,wp-controller;
	};

	sai@30010000 {
		compatible = "fsl,imx8mq-sai", "fsl,imx6sx-sai";
		reg = <0x0 0x30010000 0x0 0x10000>;
		interrupts = <0x0 0x5f 0x4>;
		clocks = <0x3 0x196 0x3 0x0 0x3 0x195 0x3 0x0 0x3 0x0>;
		clock-names = "bus", "mclk0", "mclk1", "mclk2", "mclk3";
		dmas = <0x38 0x0 0x2 0x0 0x38 0x1 0x2 0x0>;
		dma-names = "rx", "tx";
		fsl,dataline = <0x0 0xff 0xff>;
		status = "disabled";
	};

	sai@30020000 {
		compatible = "fsl,imx8mq-sai", "fsl,imx6sx-sai";
		reg = <0x0 0x30020000 0x0 0x10000>;
		interrupts = <0x0 0x60 0x4>;
		clocks = <0x3 0x198 0x3 0x0 0x3 0x197 0x3 0x0 0x3 0x0>;
		clock-names = "bus", "mclk0", "mclk1", "mclk2", "mclk3";
		dmas = <0x38 0x2 0x2 0x0 0x38 0x3 0x2 0x0>;
		dma-names = "rx", "tx";
		status = "okay";
		pinctrl-names = "default";
		pinctrl-0 = <0x39>;
		#sound-dai-cells = <0x0>;
		linux,phandle = <0x55>;
		phandle = <0x55>;
	};

	sai@30030000 {
		compatible = "fsl,imx8mm-sai", "fsl,imx8mq-sai", "fsl,imx6sx-sai";
		reg = <0x0 0x30030000 0x0 0x10000>;
		interrupts = <0x0 0x32 0x4>;
		clocks = <0x3 0x19a 0x3 0x0 0x3 0x199 0x3 0x0 0x3 0x0>;
		clock-names = "bus", "mclk0", "mclk1", "mclk2", "mclk3";
		dmas = <0x38 0x4 0x2 0x0 0x38 0x5 0x2 0x0>;
		dma-names = "rx", "tx";
		status = "disabled";
	};

	sai@30050000 {
		compatible = "fsl,imx8mm-sai", "fsl,imx8mq-sai", "fsl,imx6sx-sai";
		reg = <0x0 0x30050000 0x0 0x10000>;
		interrupts = <0x0 0x5a 0x4>;
		clocks = <0x3 0x19e 0x3 0x0 0x3 0x19d 0x3 0x0 0x3 0x0>;
		clock-names = "bus", "mclk0", "mclk1", "mclk2", "mclk3";
		dmas = <0x38 0x8 0x2 0x0 0x38 0x9 0x2 0x0>;
		dma-names = "rx", "tx";
		fsl,shared-interrupt;
		fsl,dataline = <0x0 0xf 0xf>;
		status = "disabled";
	};

	sai@30060000 {
		compatible = "fsl,imx8mq-sai", "fsl,imx6sx-sai";
		reg = <0x0 0x30060000 0x0 0x10000>;
		interrupts = <0x0 0x5a 0x4>;
		clocks = <0x3 0x1a0 0x3 0x0 0x3 0x19f 0x3 0x0 0x3 0x0>;
		clock-names = "bus", "mclk0", "mclk1", "mclk2", "mclk3";
		dmas = <0x38 0xa 0x2 0x0 0x38 0xb 0x2 0x0>;
		dma-names = "rx", "tx";
		fsl,shared-interrupt;
		status = "disabled";
	};

	micfil@30080000 {
		compatible = "fsl,imx8mm-micfil";
		reg = <0x0 0x30080000 0x0 0x10000>;
		interrupts = <0x0 0x2c 0x4 0x0 0x2d 0x4 0x0 0x6d 0x4 0x0 0x6e 0x4>;
		clocks = <0x3 0x1bd 0x3 0x1b0 0x3 0x26 0x3 0x27 0x3 0x6>;
		clock-names = "ipg_clk", "ipg_clk_app", "pll8k", "pll11k", "clkext3";
		dmas = <0x38 0x18 0x1a 0x80000000>;
		dma-names = "rx";
		status = "disabled";
	};

	spdif@30090000 {
		compatible = "fsl,imx8mm-spdif";
		reg = <0x0 0x30090000 0x0 0x10000>;
		interrupts = <0x0 0x6 0x4>;
		clocks = <0x3 0x8b 0x3 0x2 0x3 0x158 0x3 0x0 0x3 0x0 0x3 0x0 0x3 0x8b 0x3 0x0 0x3 0x0 0x3 0x0>;
		clock-names = "core", "rxtx0", "rxtx1", "rxtx2", "rxtx3", "rxtx4", "rxtx5", "rxtx6", "rxtx7", "spba";
		dmas = <0x38 0x1c 0x12 0x0 0x38 0x1d 0x12 0x0>;
		dma-names = "rx", "tx";
		status = "disabled";
	};

	dma-controller@30bd0000 {
		compatible = "fsl,imx8mm-sdma", "fsl,imx8mq-sdma", "fsl,imx7d-sdma";
		reg = <0x0 0x30bd0000 0x0 0x10000>;
		interrupts = <0x0 0x2 0x4>;
		clocks = <0x3 0x1b8 0x3 0x1b8>;
		clock-names = "ipg", "ahb";
		#dma-cells = <0x3>;
		fsl,sdma-ram-script-name = "imx/sdma/sdma-imx7d.bin";
		status = "okay";
		linux,phandle = <0x17>;
		phandle = <0x17>;
	};

	dma-controller@302c0000 {
		compatible = "fsl,imx8mm-sdma", "fsl,imx8mq-sdma", "fsl,imx7d-sdma";
		reg = <0x0 0x302c0000 0x0 0x10000>;
		interrupts = <0x0 0x67 0x4>;
		clocks = <0x3 0x1b9 0x3 0x1b9>;
		clock-names = "ipg", "ahb";
		#dma-cells = <0x3>;
		fsl,sdma-ram-script-name = "imx/sdma/sdma-imx7d.bin";
		fsl,ratio-1-1;
		status = "okay";
		linux,phandle = <0x38>;
		phandle = <0x38>;
	};

	dma-controller@302b0000 {
		compatible = "fsl,imx8mm-sdma", "fsl,imx8mq-sdma", "fsl,imx7d-sdma";
		reg = <0x0 0x302b0000 0x0 0x10000>;
		interrupts = <0x0 0x22 0x4>;
		clocks = <0x3 0x1ba 0x3 0x1ba>;
		clock-names = "ipg", "ahb";
		#dma-cells = <0x3>;
		fsl,sdma-ram-script-name = "imx/sdma/sdma-imx7d.bin";
		fsl,ratio-1-1;
		status = "okay";
	};

	wdog@30280000 {
		compatible = "fsl,imx21-wdt";
		reg = <0x0 0x30280000 0x0 0x10000>;
		interrupts = <0x0 0x4e 0x4>;
		clocks = <0x3 0x1a9>;
		status = "okay";
		pinctrl-names = "default";
	};

	wdog@30290000 {
		compatible = "fsl,imx21-wdt";
		reg = <0x0 0x30290000 0x0 0x10000>;
		interrupts = <0x0 0x4f 0x4>;
		clocks = <0x3 0x1aa>;
		status = "disabled";
	};

	wdog@302a0000 {
		compatible = "fsl,imx21-wdt";
		reg = <0x0 0x302a0000 0x0 0x10000>;
		interrupts = <0x0 0xa 0x4>;
		clocks = <0x3 0x1ab>;
		status = "disabled";
	};

	flexspi@30bb0000 {
		#address-cells = <0x1>;
		#size-cells = <0x0>;
		compatible = "fsl,imx8mm-flexspi";
		reg = <0x0 0x30bb0000 0x0 0x10000 0x0 0x8000000 0x0 0x10000000>;
		reg-names = "FlexSPI", "FlexSPI-memory";
		interrupts = <0x0 0x6b 0x4>;
		clocks = <0x3 0x193>;
		clock-names = "fspi";
		status = "disabled";
	};

	ecspi@30820000 {
		#address-cells = <0x1>;
		#size-cells = <0x0>;
		compatible = "fsl,imx8mm-ecspi", "fsl,imx51-ecspi";
		reg = <0x0 0x30820000 0x0 0x10000>;
		interrupts = <0x0 0x1f 0x4>;
		clocks = <0x3 0x184 0x3 0x184>;
		clock-names = "ipg", "per";
		dmas = <0x17 0x0 0x7 0x1 0x17 0x1 0x7 0x2>;
		dma-names = "rx", "tx";
		status = "disabled";
	};

	ecspi@30830000 {
		#address-cells = <0x1>;
		#size-cells = <0x0>;
		compatible = "fsl,imx8mm-ecspi", "fsl,imx51-ecspi";
		reg = <0x0 0x30830000 0x0 0x10000>;
		interrupts = <0x0 0x20 0x4>;
		clocks = <0x3 0x185 0x3 0x185>;
		clock-names = "ipg", "per";
		dmas = <0x17 0x2 0x7 0x1 0x17 0x3 0x7 0x2>;
		dma-names = "rx", "tx";
		cs-gpios = <0x44 0x0d 0x01>;
		status = "okay";
	};

	ecspi@30840000 {
		#address-cells = <0x1>;
		#size-cells = <0x0>;
		compatible = "fsl,imx8mm-ecspi", "fsl,imx51-ecspi";
		reg = <0x0 0x30840000 0x0 0x10000>;
		interrupts = <0x0 0x21 0x4>;
		clocks = <0x3 0x186 0x3 0x186>;
		clock-names = "ipg", "per";
		dmas = <0x17 0x4 0x7 0x1 0x17 0x5 0x7 0x2>;
		dma-names = "rx", "tx";
		status = "disabled";
	};

	ethernet@30be0000 {
		compatible = "fsl,imx8mm-fec", "fsl,imx8mq-fec", "fsl,imx6sx-fec";
		reg = <0x0 0x30be0000 0x0 0x10000>;
		interrupts = <0x0 0x76 0x4 0x0 0x77 0x4 0x0 0x78 0x4>;
		clocks = <0x3 0x187 0x3 0x187 0x3 0x15b 0x3 0x15a 0x3 0x15c>;
		clock-names = "ipg", "ahb", "ptp", "enet_clk_ref", "enet_out";
		assigned-clocks = <0x3 0x52 0x3 0xa4 0x3 0xa3 0x3 0x15b>;
		assigned-clock-parents = <0x3 0x36 0x3 0x3a 0x3 0x39>;
		assigned-clock-rates = <0x0 0x0 0x2faf080 0x5f5e100>;
		stop-mode = <0x3a 0x10 0x3>;
		fsl,num-tx-queues = <0x3>;
		fsl,num-rx-queues = <0x3>;
		fsl,wakeup_irq = <0x2>;
		status = "okay";
		pinctrl-names = "default", "sleep";
		pinctrl-0 = <0x3b 0x3c>;
		pinctrl-1 = <0x3d>;
		phy-mode = "rmii";
		phy-handle = <0x3e>;
		phy-supply = <0x3f>;
		phy-reset-gpios = <0x21 0x1d 0x1>;
		phy-reset-duration = <0xa>;

		mdio {
			#address-cells = <0x1>;
			#size-cells = <0x0>;

			ethernet-phy@0 {
				compatible = "ethernet-phy-ieee802.3-c22";
				reg = <0x0>;
				pinctrl-names = "default";
				pinctrl-0 = <0x40>;
				interrupt-parent = <0x21>;
				interrupts = <0x1c 0x2>;
				smsc,disable-energy-detect;
				linux,phandle = <0x3e>;
				phandle = <0x3e>;
			};
		};
	};

	dma_cap {
		compatible = "dma-capability";
		only-dma-mask32 = <0x1>;
	};

	imx_ion {
		compatible = "fsl,mxc-ion";
		fsl,heap-id = <0x0>;
	};

	lcdif@32E00000 {
		#address-cells = <0x1>;
		#size-cells = <0x0>;
		compatible = "fsl,imx8mm-lcdif";
		reg = <0x0 0x32e00000 0x0 0x10000>;
		clocks = <0x3 0x151 0x3 0x1b2 0x3 0x1b3>;
		clock-names = "pix", "disp-axi", "disp-apb";
		assigned-clocks = <0x3 0x9a 0x3 0x55 0x3 0x56>;
		assigned-clock-parents = <0x3 0x28 0x3 0x41 0x3 0x38>;
		assigned-clock-rate = <0x2367b880 0x1dcd6500 0xbebc200>;
		interrupts = <0x0 0x5 0x4>;
		lcdif-gpr = <0xb>;
		power-domains = <0xa>;
		status = "okay";

		port@0 {
			reg = <0x0>;
			linux,phandle = <0x46>;
			phandle = <0x46>;

			endpoint {
				remote-endpoint = <0x41>;
				linux,phandle = <0x42>;
				phandle = <0x42>;
			};
		};
	};

	mipi_dsi@32E10000 {
		#address-cells = <0x1>;
		#size-cells = <0x0>;
		compatible = "fsl,imx8mm-mipi-dsim";
		reg = <0x0 0x32e10000 0x0 0x400>;
		clocks = <0x3 0x174 0x3 0x175>;
		clock-names = "cfg", "pll-ref";
		assigned-clocks = <0x3 0xbd 0x3 0xbe>;
		assigned-clock-parents = <0x3 0x36 0x3 0x28>;
		assigned-clock-rates = <0xfdad680 0x2367b880>;
		interrupts = <0x0 0x12 0x4>;
		dsi-gpr = <0xb>;
		power-domains = <0xc>;
		status = "okay";

		port@0 {

			endpoint {
				remote-endpoint = <0x42>;
				linux,phandle = <0x41>;
				phandle = <0x41>;
			};
		};

		panel@0 {
			compatible = "tianma,tm101jvhg32";
			pinctrl-names = "default";
			pinctrl-0 = <0x43>;
			reg = <0x0>;
			panel-width-mm = <0xd9>;
			panel-height-mm = <0x88>;
			enable-gpios = <0x44 0x14 0x1>;
			backlight = <0x45>;
			status = "okay";
		};
	};

	display-subsystem {
		compatible = "fsl,imx-display-subsystem";
		ports = <0x46>;
	};

	pcie@0x33800000 {
		compatible = "fsl,imx8mm-pcie", "snps,dw-pcie";
		reg = <0x0 0x33800000 0x0 0x400000 0x0 0x32f00000 0x0 0x10000 0x0 0x1ff00000 0x0 0x80000>;
		reg-names = "dbi", "phy", "config";
		reserved-region = <0x47>;
		#address-cells = <0x3>;
		#size-cells = <0x2>;
		device_type = "pci";
		ranges = <0x81000000 0x0 0x0 0x0 0x1ff80000 0x0 0x10000 0x82000000 0x0 0x18000000 0x0 0x18000000 0x0 0x7f00000>;
		num-lanes = <0x1>;
		interrupts = <0x0 0x7a 0x4 0x0 0x7f 0x4>;
		interrupt-names = "msi";
		#interrupt-cells = <0x1>;
		interrupt-map-mask = <0x0 0x0 0x0 0x7>;
		interrupt-map = <0x0 0x0 0x0 0x1 0x9 0x0 0x7d 0x4 0x0 0x0 0x0 0x2 0x9 0x0 0x7c 0x4 0x0 0x0 0x0 0x3 0x9 0x0 0x7b 0x4 0x0 0x0 0x0 0x4 0x9 0x0 0x7a 0x4>;
		clocks = <0x3 0x18e 0x3 0xd5 0x3 0xd4>;
		clock-names = "pcie", "pcie_bus", "pcie_phy";
		bus-range = <0x0 0xff>;
		fsl,max-link-speed = <0x2>;
		ctrl-id = <0x0>;
		power-domains = <0x48>;
		status = "disabled";
	};

	pwm@30660000 {
		compatible = "fsl,imx8mm-pwm", "fsl,imx27-pwm";
		reg = <0x0 0x30660000 0x0 0x10000>;
		interrupts = <0x0 0x51 0x4>;
		clocks = <0x3 0x18f 0x3 0x18f>;
		clock-names = "ipg", "per";
		#pwm-cells = <0x2>;
		status = "okay";
		pinctrl-names = "default";
		pinctrl-0 = <0x49>;
		linux,phandle = <0x52>;
		phandle = <0x52>;
	};

	pwm@30670000 {
		compatible = "fsl,imx8mm-pwm", "fsl,imx27-pwm";
		reg = <0x0 0x30670000 0x0 0x10000>;
		interrupts = <0x0 0x52 0x4>;
		clocks = <0x3 0x190 0x3 0x190>;
		clock-names = "ipg", "per";
		#pwm-cells = <0x2>;
		status = "disabled";
	};

	pwm@30680000 {
		compatible = "fsl,imx8mm-pwm", "fsl,imx27-pwm";
		reg = <0x0 0x30680000 0x0 0x10000>;
		interrupts = <0x0 0x53 0x4>;
		clocks = <0x3 0x191 0x3 0x191>;
		clock-names = "ipg", "per";
		#pwm-cells = <0x2>;
		status = "disabled";
	};

	pwm@30690000 {
		compatible = "fsl,imx8mm-pwm", "fsl,imx27-pwm";
		reg = <0x0 0x30690000 0x0 0x10000>;
		interrupts = <0x0 0x54 0x4>;
		clocks = <0x3 0x192 0x3 0x192>;
		clock-names = "ipg", "per";
		#pwm-cells = <0x2>;
		status = "disabled";
	};

	vpu_h1@38320000 {
		compatible = "nxp,imx8mm-hantro-h1";
		reg = <0x0 0x38320000 0x0 0x10000>;
		reg-names = "regs_hantro_h1";
		interrupts = <0x0 0x1e 0x4>;
		interrupt-names = "irq_hantro_h1";
		clocks = <0x3 0x1ae 0x3 0x1b7>;
		clock-names = "clk_hantro_h1", "clk_hantro_h1_bus";
		assigned-clocks = <0x3 0xcc 0x3 0x54>;
		assigned-clock-parents = <0x3 0x2b 0x3 0x38>;
		assigned-clock-rates = <0x23c34600 0x2faf0800>;
		power-domains = <0x4a>;
		status = "okay";
	};

	vpu_g1@38300000 {
		compatible = "nxp,imx8mm-hantro";
		reg = <0x0 0x38300000 0x0 0x100000>;
		reg-names = "regs_hantro";
		interrupts = <0x0 0x7 0x4>;
		interrupt-names = "irq_hantro";
		clocks = <0x3 0x1ac 0x3 0x1b7>;
		clock-names = "clk_hantro", "clk_hantro_bus";
		assigned-clocks = <0x3 0x92 0x3 0x54>;
		assigned-clock-parents = <0x3 0x2b 0x3 0x38>;
		assigned-clock-rates = <0x23c34600 0x2faf0800>;
		power-domains = <0x4b>;
		status = "okay";
	};

	vpu_g2@38310000 {
		compatible = "nxp,imx8mm-hantro";
		reg = <0x0 0x38310000 0x0 0x100000>;
		reg-names = "regs_hantro";
		interrupts = <0x0 0x8 0x4>;
		interrupt-names = "irq_hantro";
		clocks = <0x3 0x1af 0x3 0x1b7>;
		clock-names = "clk_hantro", "clk_hantro_bus";
		assigned-clocks = <0x3 0x93 0x3 0x54>;
		assigned-clock-parents = <0x3 0x2b 0x3 0x38>;
		assigned-clock-rates = <0x23c34600 0x2faf0800>;
		power-domains = <0x4c>;
		status = "okay";
	};

	gpu@38000000 {
		compatible = "fsl,imx8mm-gpu", "fsl,imx6q-gpu";
		reg = <0x0 0x38000000 0x0 0x8000 0x0 0x38008000 0x0 0x8000 0x0 0x40000000 0x0 0x80000000 0x0 0x0 0x0 0x8000000>;
		reg-names = "iobase_3d", "iobase_2d", "phys_baseaddr", "contiguous_mem";
		interrupts = <0x0 0x3 0x4 0x0 0x19 0x4>;
		interrupt-names = "irq_3d", "irq_2d";
		clocks = <0x3 0x1a6 0x3 0x0 0x3 0x1ad 0x3 0x7e 0x3 0x1be 0x3 0x1ad 0x3 0x7e>;
		clock-names = "gpu3d_clk", "gpu3d_shader_clk", "gpu3d_axi_clk", "gpu3d_ahb_clk", "gpu2d_clk", "gpu2d_axi_clk", "gpu2d_ahb_clk";
		assigned-clocks = <0x3 0x45 0x3 0x46 0x3 0x59 0x3 0x5a 0x3 0x2a 0x3 0x7e>;
		assigned-clock-parents = <0x3 0x2a 0x3 0x2a 0x3 0x38 0x3 0x38>;
		assigned-clock-rates = <0x0 0x0 0x0 0x0 0x3b9aca00 0x17d78400>;
		power-domains = <0x4d>;
		status = "okay";
	};

	caam@30900000 {
		compatible = "fsl,sec-v4.0";
		#address-cells = <0x1>;
		#size-cells = <0x1>;
		reg = <0x0 0x30900000 0x0 0x40000>;
		ranges = <0x0 0x0 0x30900000 0x40000>;
		interrupts = <0x0 0x5b 0x4>;

		jr0@1000 {
			compatible = "fsl,sec-v4.0-job-ring";
			reg = <0x1000 0x1000>;
			interrupts = <0x0 0x69 0x4>;
		};

		jr1@2000 {
			compatible = "fsl,sec-v4.0-job-ring";
			reg = <0x2000 0x1000>;
			interrupts = <0x0 0x6a 0x4>;
		};

		jr2@3000 {
			compatible = "fsl,sec-v4.0-job-ring";
			reg = <0x3000 0x1000>;
			interrupts = <0x0 0x72 0x4>;
		};
	};

	caam-sm@00100000 {
		compatible = "fsl,imx6q-caam-sm";
		reg = <0x0 0x100000 0x0 0x8000>;
	};

	caam-snvs@30370000 {
		compatible = "fsl,imx6q-caam-snvs";
		reg = <0x0 0x30370000 0x0 0x10000>;
	};

	caam_secvio {
		compatible = "fsl,imx7d-caam-secvio", "fsl,imx6q-caam-secvio";
		interrupts = <0x0 0x14 0x4>;
		jtag-tamper = "disabled";
		watchdog-tamper = "enabled";
		internal-boot-tamper = "enabled";
		external-pin-tamper = "disabled";
	};

	dma-apbh@33000000 {
		compatible = "fsl,imx7d-dma-apbh", "fsl,imx28-dma-apbh";
		reg = <0x0 0x33000000 0x0 0x2000>;
		interrupts = <0x0 0xc 0x4 0x0 0xc 0x4 0x0 0xc 0x4 0x0 0xc 0x4>;
		interrupt-names = "gpmi0", "gpmi1", "gpmi2", "gpmi3";
		#dma-cells = <0x1>;
		dma-channels = <0x4>;
		clocks = <0x3 0x1c7>;
		linux,phandle = <0x4e>;
		phandle = <0x4e>;
	};

	gpmi-nand@33002000 {
		compatible = "fsl,imx7d-gpmi-nand";
		#address-cells = <0x1>;
		#size-cells = <0x1>;
		reg = <0x0 0x33002000 0x0 0x2000 0x0 0x33004000 0x0 0x4000>;
		reg-names = "gpmi-nand", "bch";
		interrupts = <0x0 0xe 0x4>;
		interrupt-names = "bch";
		clocks = <0x3 0x194 0x3 0x1c7>;
		clock-names = "gpmi_io", "gpmi_bch_apb";
		dmas = <0x4e 0x0>;
		dma-names = "rx-tx";
		status = "disabled";
	};

	chosen {
		bootargs = "console=ttymxc0,115200 earlycon=ec_imx6q,0x30860000,115200";
		stdout-path = "/serial@30860000";
	};

	owire {
		compatible = "w1-gpio";
		pinctrl-names = "default";
		pinctrl-0 = <0x4f>;
		gpios = <0x37 0x19 0x0>;
		linux,open-drain;
	};

	regulator-3v3 {
		compatible = "regulator-fixed";
		regulator-name = "3V3";
		regulator-min-microvolt = <0x325aa0>;
		regulator-max-microvolt = <0x325aa0>;
		regulator-always-on;
		power-supply = <0x50>;
		linux,phandle = <0x24>;
		phandle = <0x24>;
	};

	regulator-3v3-etn {
		compatible = "regulator-fixed";
		regulator-name = "3V3_ETN";
		regulator-min-microvolt = <0x325aa0>;
		regulator-max-microvolt = <0x325aa0>;
		pinctrl-names = "default";
		pinctrl-0 = <0x51>;
		gpio = <0x21 0x17 0x0>;
		enable-active-high;
		power-supply = <0x24>;
		linux,phandle = <0x3f>;
		phandle = <0x3f>;
	};

	backlight {
		compatible = "pwm-backlight";
		pwms = <0x52 0x0 0x7a120>;
		turn-on-delay-ms = <0x23>;
		power-supply = <0x24>;
		brightness-levels = <0x0 0x1 0x2 0x3 0x4 0x5 0x6 0x7 0x8 0x9 0xa 0xb 0xc 0xd 0xe 0xf 0x10 0x11 0x12 0x13 0x14 0x15 0x16 0x17 0x18 0x19 0x1a 0x1b 0x1c 0x1d 0x1e 0x1f 0x20 0x21 0x22 0x23 0x24 0x25 0x26 0x27 0x28 0x29 0x2a 0x2b 0x2c 0x2d 0x2e 0x2f 0x30 0x31 0x32 0x33 0x34 0x35 0x36 0x37 0x38 0x39 0x3a 0x3b 0x3c 0x3d 0x3e 0x3f 0x40 0x41 0x42 0x43 0x44 0x45 0x46 0x47 0x48 0x49 0x4a 0x4b 0x4c 0x4d 0x4e 0x4f 0x50 0x51 0x52 0x53 0x54 0x55 0x56 0x57 0x58 0x59 0x5a 0x5b 0x5c 0x5d 0x5e 0x5f 0x60 0x61 0x62 0x63 0x64>;
		default-brightness-level = <0x32>;
		linux,phandle = <0x45>;
		phandle = <0x45>;
	};

	leds {
		compatible = "gpio-leds";

		stk5led {
			label = "Heartbeat";
			pinctrl-names = "default";
			pinctrl-0 = <0x53>;
			gpios = <0x21 0x2 0x0>;
			linux,default-trigger = "heartbeat";
		};
	};

	regulator-2v5 {
		compatible = "regulator-fixed";
		regulator-name = "2V5";
		regulator-min-microvolt = <0x2625a0>;
		regulator-max-microvolt = <0x2625a0>;
		regulator-always-on;
		power-supply = <0x24>;
		linux,phandle = <0x23>;
		phandle = <0x23>;
	};

	sound {
		compatible = "karo,imx8mm-tx8m-sgtl5000", "simple-audio-card";
		simple-audio-card,name = "imx8mm-tx8m-sgtl5000-audio";
		simple-audio-card,format = "i2s";
		simple-audio-card,bitclock-master = <0x54>;
		simple-audio-card,frame-master = <0x54>;
		simple-audio-card,widgets = "Microphone", "Mic Jack", "Line", "Line In", "Line", "Line Out", "Headphone", "Headphone Jack";
		simple-audio-card,routing = "MIC_IN", "Mic Jack", "Mic Jack", "Mic Bias", "Headphone Jack", "HP_OUT";

		simple-audio-card,cpu {
			sound-dai = <0x55>;
		};

		simple-audio-card,codec {
			sound-dai = <0x56>;
			linux,phandle = <0x54>;
			phandle = <0x54>;
		};
	};
};
